# nrf54h20_engb_application register map
Vendor: Nordic Semiconductor; Series: nRF54h; File version: 1
CPU: CM33 r0p4, little endian, MPU, FPU, 3 interrupt priority bits, 480 interrupts, 8 SAU regions
Registers are 32-bit, read-write, reset 0x0 unless marked. A register's access mark holds for its fields unless they carry their own. Offsets are from the block's base; [hi:lo] are bit positions; {n}, {i} and the like mark numbered series.

## GLOBAL_GPR_NS — Granular Power Requester
Base 0xBF050000
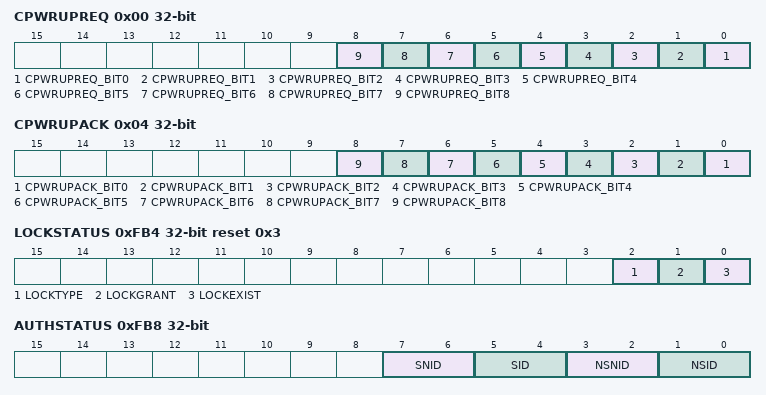
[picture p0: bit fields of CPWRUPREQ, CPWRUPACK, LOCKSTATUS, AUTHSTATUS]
0x00 CPWRUPREQ — Debug Power Request Register
  [n] CPWRUPREQ_BIT{n} (n=0..8) — Bit {n} of the cpwrupreq output port.
0x04 CPWRUPACK ro — Debug Power Acknowledge Register
  [n] CPWRUPACK_BIT{n} (n=0..8) — Bit {n} of the cpwrupack input port.
0xF00 ITCTRL ro — Integration Mode Control Register
  [0] INTEGRATION_MODE — When you read this register, CXGPR returns a zero because no integration functionality is implemented.
0xFA0 CLAIMSET reset 0xF — Claim Tag Set Register
  [3:0] CLAIMSET — On Read for each bit 1 means claim tag bit implemented. On Write for each bit 0 has no effect, 1 sets the relevant bit of the claim tag
0xFA4 CLAIMCLR ro — Claim Tag Clear Register
  [3:0] CLAIMCLR — The value present reflects the present value of the Claim Tag.
0xFB0 LOCKACCESS wo
  [31:0] LOCKACCESS — When you write 0xC5ACCE55, subsequent write operations to this device are enabled. Any other value disables subsequent write operations.
0xFB4 LOCKSTATUS ro reset 0x3
  [2] LOCKTYPE — Indicates that the Lock Access Register is implemented as 32-bit.
  [1] LOCKGRANT — Returns the present lock status of the device.
  [0] LOCKEXIST — Indicates that a lock control mechanism is present in this device.
0xFB8 AUTHSTATUS ro — Authentication Status Register
  [7:6] SNID — Indicates the security level for Secure Non-Invasive Debug.
  [5:4] SID — Indicates the security level for Secure Invasive Debug.
  [3:2] NSNID — Indicates the security level for Non-Secure Non-Invasive Debug.
  [1:0] NSID — Indicates the security level for Non-Secure Invasive Debug.
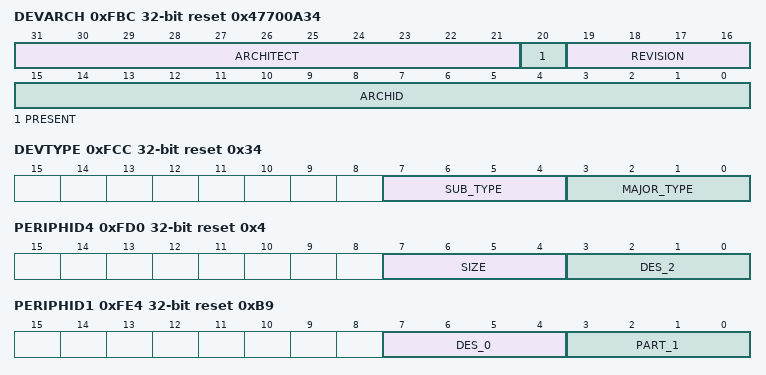
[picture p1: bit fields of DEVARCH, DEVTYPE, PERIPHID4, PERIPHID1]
0xFBC DEVARCH ro reset 0x47700A34 — Device Architecture Register
  [31:21] ARCHITECT — Indicates the JEP106 code pf the architect who specifies the architecture of the component. Bits [31:28] are the JEP106 continuation code. Bits [27:21] are the JEP106 identity code.
  [20] PRESENT — Indicates whether the DEVARCH register is present.
  [19:16] REVISION — Indicates the revision of the architecture.
  [15:0] ARCHID — Indicates the architecture of the component.
0xFC8 DEVID ro reset 0x1 — Device Configuration Register
  [5:0] CPWRUPM_COUNT — The value present in this field indicates the number of CPWRUP master interfaces available in CXGPR. Permitted range of values: 0x1 to 0x20.
0xFCC DEVTYPE ro reset 0x34 — Device Type Identifier Register
  [7:4] SUB_TYPE — Sub-classification of the type of the debug component as specified in the CoreSight Architecture Specification within the major classification as specified in the Major_Type field.
  [3:0] MAJOR_TYPE — Major classification of the type of the debug component as specified in the CoreSight Architecture Specification for this debug and trace component.
0xFD0 PERIPHID4 ro reset 0x4 — Peripheral ID4 Register
  [7:4] SIZE — This is a 4-bit value that indicates the total contiguous size in powers of two of the memory window that this component uses from the standard 4KB. If a component only requires the standard 4KB size then this reads as 0x0, for 8KB: 0x1, 16KB:0x2, 32KB: 0x3, until 128MB.
  [3:0] DES_2 — This is the JEDEC JEP106 continuation code. This code along with, bits[6:4] of the identity code defined in PERIPHID0 register. and with bits[3:0] of the identity code defined in PERIPHID1 register, gives the designer of the component.
0xFE0 PERIPHID0 ro reset 0xA4 — Peripheral ID0 Register
  [7:0] PART_0 — Bits [7:0] of the components 12 bit part number. The designer of the component assigns this part number.
0xFE4 PERIPHID1 ro reset 0xB9 — Peripheral ID1 Register
  [7:4] DES_0 — Bits[3:0] of the JEDEC JEP106 identity code. This code, along with bits[6:4] of the identity code defined in PERIPHID2 register and the continuation code defined in PERIPHID4 register, gives the designer of the component.
  [3:0] PART_1 — Bits[11:8] of the components 12 bit part number. The designer of the component assigns this part number.
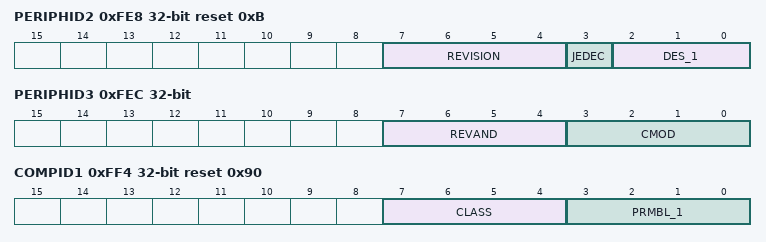
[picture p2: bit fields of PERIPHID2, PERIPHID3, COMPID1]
0xFE8 PERIPHID2 ro reset 0xB — Peripheral ID2 Register
  [7:4] REVISION — An incremental value starting from 0x0 for the first revision of this component. This increases by 1 for both major and minor revisions and is used to identify the major or minor revisions.
  [3] JEDEC — Always set. Indicates if the JEDEC assigned designer ID is used.
  [2:0] DES_1 — Bits[6:4] of the JEDEC JEP106 identity code. This code, along with bits[3:0] of the identity code defined in PERIPHID1 register and the continuation code defined in PERIPHID4 register, gives the designer of the component.
0xFEC PERIPHID3 ro — Peripheral ID3 Register
  [7:4] REVAND — Indicates minor errata fixes specific to the revision of the component being used, for example metal fixes after implementation. In most cases, this field might be zero. ARM recommends that the component designers ensure that a metal fix can change this field if required, for example, by driving it from registers that reset to zero.
  [3:0] CMOD — Indicates if the customer modified the behavior of the component. In most cases, this field might be zero. The customer changes this value on modifications to this component.
0xFF0 COMPID0 ro reset 0xD — Component ID0 Register
  [7:0] PRMBL_0 — Contains bits[7:0] of the component identification code.
0xFF4 COMPID1 ro reset 0x90 — Component ID1 Register
  [7:4] CLASS — Class of the component, for example, if the component is a ROM table or a generic CoreSight component. Contains bits[15:12] of the component identification code.
  [3:0] PRMBL_1 — Contains bits [11:8] of the component identification
0xFF8 COMPID2 ro reset 0x5 — Component ID2 Register
  [7:0] PRMBL_2 — Contains bits [23:16] of the component identification
0xFFC COMPID3 ro reset 0xB1 — Component ID3 Register
  [7:0] PRMBL_3 — Contains bits [31:24] of the component identification
